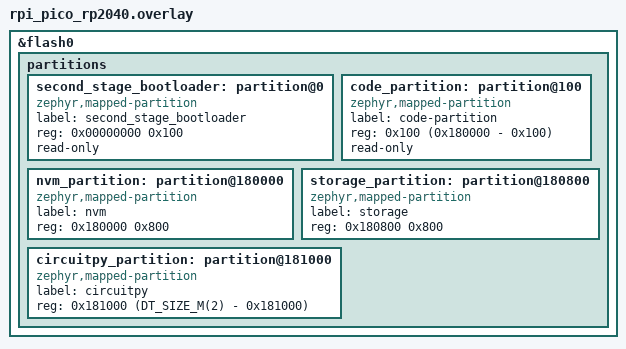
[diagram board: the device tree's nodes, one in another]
&flash0 {
	/delete-node/ partitions;

	partitions {
		/*
		 * The RP2040 flash is memory mapped at 0x10000000 and flash0 carries
		 * "ranges" to express that. Re-creating "partitions" after
		 * /delete-node/ drops the "ranges" the stock rpi_pico-common.dtsi puts
		 * here, which breaks address translation for the
		 * "zephyr,mapped-partition" children: DT_REG_ADDR(code_partition)
		 * would then return the bare 0x100 offset instead of 0x10000100. That
		 * links the image at 0x100 (ROM_ADDR in cortex_m/scripts/linker.ld)
		 * and makes RP2_REQUIRES_SECOND_STAGE_BOOT default to n, so no .boot2
		 * is emitted at 0x10000000 and the resulting UF2 does not boot.
		 */
		ranges;
		#address-cells = <1>;
		#size-cells = <1>;

		/* Reserved memory for the second stage bootloader */
		second_stage_bootloader: partition@0 {
			compatible = "zephyr,mapped-partition";
			label = "second_stage_bootloader";
			reg = <0x00000000 0x100>;
			read-only;
		};

		code_partition: partition@100 {
			compatible = "zephyr,mapped-partition";
			label = "code-partition";
			reg = <0x100 (0x180000 - 0x100)>;
			read-only;
		};

		nvm_partition: partition@180000 {
			compatible = "zephyr,mapped-partition";
			label = "nvm";
			reg = <0x180000 0x800>;
		};

		storage_partition: partition@180800 {
			compatible = "zephyr,mapped-partition";
			label = "storage";
			reg = <0x180800 0x800>;
		};

		circuitpy_partition: partition@181000 {
			compatible = "zephyr,mapped-partition";
			label = "circuitpy";
			reg = <0x181000 (DT_SIZE_M(2) - 0x181000)>;
		};
	};
};

#include "../app.overlay"
